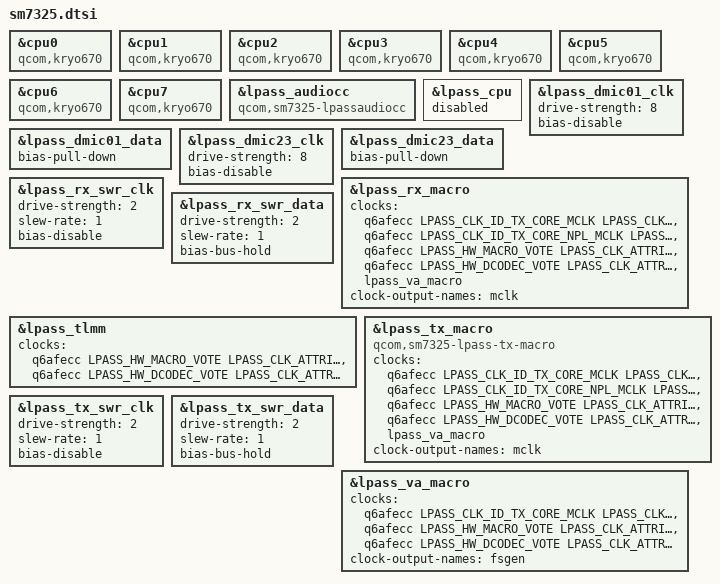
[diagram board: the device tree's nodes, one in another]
// SPDX-License-Identifier: BSD-3-Clause
/*
 * Copyright (c) 2024, Eugene Lepshy <fekz115@gmail.com>
 * Copyright (c) 2024, Danila Tikhonov <danila@jiaxyga.com>
 */

#include "sc7280.dtsi"

#include <dt-bindings/sound/qcom,q6dsp-lpass-ports.h>

/* SM7325 uses Kryo 670 */
&cpu0 { compatible = "qcom,kryo670"; };
&cpu1 { compatible = "qcom,kryo670"; };
&cpu2 { compatible = "qcom,kryo670"; };
&cpu3 { compatible = "qcom,kryo670"; };
&cpu4 { compatible = "qcom,kryo670"; };
&cpu5 { compatible = "qcom,kryo670"; };
&cpu6 { compatible = "qcom,kryo670"; };
&cpu7 { compatible = "qcom,kryo670"; };

&lpass_audiocc {
	compatible = "qcom,sm7325-lpassaudiocc",
		     "qcom,qcm6490-lpassaudiocc";
	/delete-property/ power-domains;
 };

&lpass_cpu { status = "disabled"; };

&lpass_dmic01_clk {
	drive-strength = <8>;
	bias-disable;
};

&lpass_dmic01_data {
	bias-pull-down;
};

&lpass_dmic23_clk {
	drive-strength = <8>;
	bias-disable;
};

&lpass_dmic23_data {
	bias-pull-down;
};

&lpass_rx_macro {
	clocks = <&q6afecc LPASS_CLK_ID_TX_CORE_MCLK LPASS_CLK_ATTRIBUTE_COUPLE_NO>,
		 <&q6afecc LPASS_CLK_ID_TX_CORE_NPL_MCLK LPASS_CLK_ATTRIBUTE_COUPLE_NO>,
		 <&q6afecc LPASS_HW_MACRO_VOTE LPASS_CLK_ATTRIBUTE_COUPLE_NO>,
		 <&q6afecc LPASS_HW_DCODEC_VOTE LPASS_CLK_ATTRIBUTE_COUPLE_NO>,
		 <&lpass_va_macro>;
	clock-names = "mclk", "npl", "macro", "dcodec", "fsgen";

	clock-output-names = "mclk";

	/delete-property/ power-domains;
	/delete-property/ power-domain-names;
};

&lpass_rx_swr_clk {
	drive-strength = <2>;
	slew-rate = <1>;
	bias-disable;
};

&lpass_rx_swr_data {
	drive-strength = <2>;
	slew-rate = <1>;
	bias-bus-hold;
};

&lpass_tlmm {
	clocks = <&q6afecc LPASS_HW_MACRO_VOTE LPASS_CLK_ATTRIBUTE_COUPLE_NO>,
		 <&q6afecc LPASS_HW_DCODEC_VOTE LPASS_CLK_ATTRIBUTE_COUPLE_NO>;
	clock-names = "core", "audio";
};

&lpass_tx_macro {
	compatible = "qcom,sm7325-lpass-tx-macro",
		     "qcom,sm8450-lpass-tx-macro"; // txmacro = v9.2

	clocks = <&q6afecc LPASS_CLK_ID_TX_CORE_MCLK LPASS_CLK_ATTRIBUTE_COUPLE_NO>,
		 <&q6afecc LPASS_CLK_ID_TX_CORE_NPL_MCLK LPASS_CLK_ATTRIBUTE_COUPLE_NO>,
		 <&q6afecc LPASS_HW_MACRO_VOTE LPASS_CLK_ATTRIBUTE_COUPLE_NO>,
		 <&q6afecc LPASS_HW_DCODEC_VOTE LPASS_CLK_ATTRIBUTE_COUPLE_NO>,
		 <&lpass_va_macro>;
	clock-names = "mclk", "npl", "macro", "dcodec", "fsgen";

	clock-output-names = "mclk";

	/delete-property/ power-domains;
	/delete-property/ power-domain-names;
};

&lpass_tx_swr_clk {
	drive-strength = <2>;
	slew-rate = <1>;
	bias-disable;
};

&lpass_tx_swr_data {
	drive-strength = <2>;
	slew-rate = <1>;
	bias-bus-hold;
};

&lpass_va_macro {
	clocks = <&q6afecc LPASS_CLK_ID_TX_CORE_MCLK LPASS_CLK_ATTRIBUTE_COUPLE_NO>,
		 <&q6afecc LPASS_HW_MACRO_VOTE LPASS_CLK_ATTRIBUTE_COUPLE_NO>,
		 <&q6afecc LPASS_HW_DCODEC_VOTE LPASS_CLK_ATTRIBUTE_COUPLE_NO>;
	clock-names = "mclk", "macro", "dcodec";

	clock-output-names = "fsgen";

	/delete-property/ power-domains;
	/delete-property/ power-domain-names;
};
